AUTOSAR XML (schema 00048)
package /SecurityArchitecture/ComponentTypes
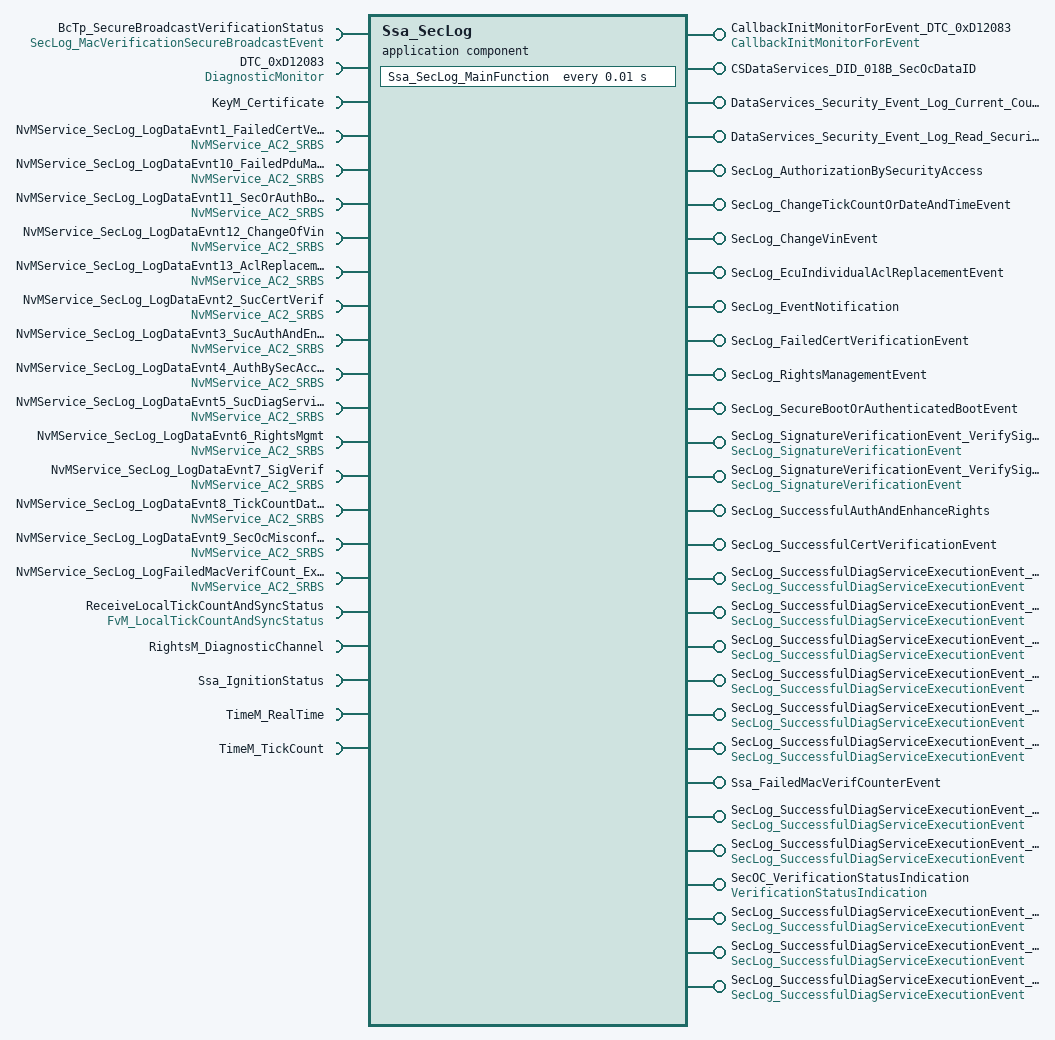
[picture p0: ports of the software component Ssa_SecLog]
  application sw component type Ssa_SecLog
    23 x provide port:
      CallbackInitMonitorForEvent_DTC_0xD12083: server-com-spec{operation=InitMonitorForEvent, queue-length=1}, provided-interface=CallbackInitMonitorForEvent  # Notifies that this event is cleared, or that the operation (monitoring) cycle restarts. Connect to corresponding event of Dem.
      CSDataServices_DID_018B_SecOcDataID: server-com-spec{operation=ReadData, queue-length=1}, provided-interface=CSDataServices_DID_018B_SecOcDataID  # Reads the SecOcDataID as Environmental Data for DTC 0xD12083. Connect to corresponding Dem port.
      DataServices_Security_Event_Log_Current_Counter_Values_Read_Security_Event_Log_Current_Counter_Values: provided-interface=DataServices_Security_Event_Log_Current_Counter_Values_Read_Security_Event_Log_Current_Counter_Values  # Reads the current counter values of the security event log.
        provided-com-specs:
          operation=ConditionCheckRead, queue-length=1
          operation=ReadData, queue-length=1
          operation=ReadDataLength, queue-length=1
      DataServices_Security_Event_Log_Read_Security_Event_Log_Entry: provided-interface=DataServices_Security_Event_Log_Read_Security_Event_Log_Entry  # Reads security event log.
        provided-com-specs:
          operation=ConditionCheckRead, queue-length=1
          operation=ReadData, queue-length=1
          operation=ReadDataLength, queue-length=1
      SecLog_AuthorizationBySecurityAccess: server-com-spec{operation=AuthorizationBySecurityAccess, queue-length=1}, provided-interface=SecLog_AuthorizationBySecurityAccess
      SecLog_ChangeTickCountOrDateAndTimeEvent: server-com-spec{operation=ChangeTickCountOrDateAndTime, queue-length=1}, provided-interface=SecLog_ChangeTickCountOrDateAndTimeEvent
      SecLog_ChangeVinEvent: server-com-spec{operation=ChangeVin, queue-length=1}, provided-interface=SecLog_ChangeVinEvent
      SecLog_EcuIndividualAclReplacementEvent: server-com-spec{operation=EcuIndividualAclReplacement, queue-length=1}, provided-interface=SecLog_EcuIndividualAclReplacementEvent
      SecLog_EventNotification: nonqueued-sender-com-spec{data-element=Data, init-value=constant-reference=Ssa_Init_Zero_7Byte}, provided-interface=SecLog_EventNotification
      SecLog_FailedCertVerificationEvent: server-com-spec{operation=FailedCertificateVerification, queue-length=1}, provided-interface=SecLog_FailedCertVerificationEvent
      SecLog_RightsManagementEvent: server-com-spec{operation=RightsManagement, queue-length=1}, provided-interface=SecLog_RightsManagementEvent
      SecLog_SecureBootOrAuthenticatedBootEvent: server-com-spec{operation=SecureBootOrAuthenticatedBoot, queue-length=1}, provided-interface=SecLog_SecureBootOrAuthenticatedBootEvent
      SecLog_SignatureVerificationEvent_VerifySignatureSwReprogramming: server-com-spec{operation=SignatureVerification, queue-length=1}, provided-interface=SecLog_SignatureVerificationEvent
      SecLog_SignatureVerificationEvent_VerifySignatureVariantCoding: server-com-spec{operation=SignatureVerification, queue-length=1}, provided-interface=SecLog_SignatureVerificationEvent
      SecLog_SuccessfulAuthAndEnhanceRights: server-com-spec{operation=SuccessfulAuthAndEnhanceRights, queue-length=1}, provided-interface=SecLog_SuccessfulAuthAndEnhanceRights
      SecLog_SuccessfulCertVerificationEvent: server-com-spec{operation=SuccessfulCertificateVerification, queue-length=1}, provided-interface=SecLog_SuccessfulCertVerificationEvent
      SecLog_SuccessfulDiagServiceExecutionEvent_ActivateDebugIf: server-com-spec{operation=SuccessfulDiagServiceExecution, queue-length=1}, provided-interface=SecLog_SuccessfulDiagServiceExecutionEvent
      SecLog_SuccessfulDiagServiceExecutionEvent_ClearSarMemory: server-com-spec{operation=SuccessfulDiagServiceExecution, queue-length=1}, provided-interface=SecLog_SuccessfulDiagServiceExecutionEvent
      SecLog_SuccessfulDiagServiceExecutionEvent_EcuSharedSecretDistribution: server-com-spec{operation=SuccessfulDiagServiceExecution, queue-length=1}, provided-interface=SecLog_SuccessfulDiagServiceExecutionEvent  # Configuration Variant(s): Not in VSM.
      SecLog_SuccessfulDiagServiceExecutionEvent_EnableSarMemOverwrite: server-com-spec{operation=SuccessfulDiagServiceExecution, queue-length=1}, provided-interface=SecLog_SuccessfulDiagServiceExecutionEvent
      SecLog_SuccessfulDiagServiceExecutionEvent_EraseMemory: server-com-spec{operation=SuccessfulDiagServiceExecution, queue-length=1}, provided-interface=SecLog_SuccessfulDiagServiceExecutionEvent
      SecLog_SuccessfulDiagServiceExecutionEvent_ReplaceCert: server-com-spec{operation=SuccessfulDiagServiceExecution, queue-length=1}, provided-interface=SecLog_SuccessfulDiagServiceExecutionEvent
      Ssa_FailedMacVerifCounterEvent: queued-sender-com-spec=Event, provided-interface=Ssa_FailedMacVerifCounterEvent
    24 x require port:
      BcTp_SecureBroadcastVerificationStatus: nonqueued-receiver-com-spec{data-element=verificationStatus, filter=data-filter-type=ALWAYS, init-value=constant-reference=Ssa_Init_SecOcVerificationState}, required-interface=SecLog_MacVerificationSecureBroadcastEvent  # Configuration Variant(s): Not in VSM.
      DTC_0xD12083: required-com-specs=[ResetEventDebounceStatus, ResetEventStatus, SetEventStatus], required-interface=DiagnosticMonitor  # Set an Event Status to failed if any one of the PDU-specific counters exceeds its configured threshold. Connect to corresponding event of Dem.
      KeyM_Certificate: required-interface=KeyM_Certificate
        required-com-specs:
          GetBackendSerialNumber
          GetBackendSubject
          VerifyCertWithBackendCert
          SignData4092ByteWithEcuPrivateKey
          VerifyCertWithBackendCert
          SignData1024ByteWithEcuPrivateKey
          CheckTrustModelChainOfTrust
      NvMService_SecLog_LogDataEvnt1_FailedCertVerif: required-com-specs=[GetErrorStatus, ReadBlock, SetRamBlockStatus, WriteBlock], required-interface=NvMService_AC2_SRBS  # Controlling the NvM block which stores the security log data of event 1, "Failed certificate verification". Connect to NvM block storing the the security log data of event 1.
      NvMService_SecLog_LogDataEvnt10_FailedPduMacVerif: required-com-specs=[GetErrorStatus, ReadBlock, SetRamBlockStatus, WriteBlock], required-interface=NvMService_AC2_SRBS  # Controlling the NvM block which stores the security log data of event 10, "Failed PDU MAC verification". Connect to NvM block storing the the security log data of event 10.
      NvMService_SecLog_LogDataEvnt11_SecOrAuthBoot: required-com-specs=[GetErrorStatus, ReadBlock, SetRamBlockStatus, WriteBlock], required-interface=NvMService_AC2_SRBS  # Controlling the NvM block which stores the security log data of event 11, "Secure boot or authenticated boot". Connect to NvM block storing the the security log data of event 11.
      NvMService_SecLog_LogDataEvnt12_ChangeOfVin: required-com-specs=[GetErrorStatus, ReadBlock, SetRamBlockStatus, WriteBlock], required-interface=NvMService_AC2_SRBS  # Controlling the NvM block which stores the security log data of event 12, "Change of VIN". Connect to NvM block storing the the security log data of event 12.
      NvMService_SecLog_LogDataEvnt13_AclReplacement: required-com-specs=[GetErrorStatus, ReadBlock, SetRamBlockStatus, WriteBlock], required-interface=NvMService_AC2_SRBS  # Controlling the NvM block which stores the security log data of event 13, "ECU-individual AccessControlList replacement". Connect to NvM block storing the the security log data of event 13.
      NvMService_SecLog_LogDataEvnt2_SucCertVerif: required-com-specs=[GetErrorStatus, ReadBlock, SetRamBlockStatus, WriteBlock], required-interface=NvMService_AC2_SRBS  # Controlling the NvM block which stores the security log data of event 2, "Successful certificate verification". Connect to NvM block storing the the security log data of event 2.
      NvMService_SecLog_LogDataEvnt3_SucAuthAndEnhanceRights: required-com-specs=[GetErrorStatus, ReadBlock, SetRamBlockStatus, WriteBlock], required-interface=NvMService_AC2_SRBS  # Controlling the NvM block which stores the security log data of event 3, "Successful authentication and enhance rights". Connect to NvM block storing the the security log data of event 3.
      NvMService_SecLog_LogDataEvnt4_AuthBySecAccess: required-com-specs=[GetErrorStatus, ReadBlock, SetRamBlockStatus, WriteBlock], required-interface=NvMService_AC2_SRBS  # Controlling the NvM block which stores the security log data of event 4, "Authorization by Security Access". Connect to NvM block storing the the security log data of event 4.
      NvMService_SecLog_LogDataEvnt5_SucDiagServiceExec: required-com-specs=[GetErrorStatus, ReadBlock, SetRamBlockStatus, WriteBlock], required-interface=NvMService_AC2_SRBS  # Controlling the NvM block which stores the security log data of event 5, "Successful diagnostic service execution". Connect to NvM block storing the the security log data of event 5.
      NvMService_SecLog_LogDataEvnt6_RightsMgmt: required-com-specs=[GetErrorStatus, ReadBlock, SetRamBlockStatus, WriteBlock], required-interface=NvMService_AC2_SRBS  # Controlling the NvM block which stores the security log data of event 6, "Rights management". Connect to NvM block storing the the security log data of event 6.
      NvMService_SecLog_LogDataEvnt7_SigVerif: required-com-specs=[GetErrorStatus, ReadBlock, SetRamBlockStatus, WriteBlock], required-interface=NvMService_AC2_SRBS  # Controlling the NvM block which stores the security log data of event 7, "Signature verification". Connect to NvM block storing the the security log data of event 7.
      NvMService_SecLog_LogDataEvnt8_TickCountDateAndTime: required-com-specs=[GetErrorStatus, ReadBlock, SetRamBlockStatus, WriteBlock], required-interface=NvMService_AC2_SRBS  # Controlling the NvM block which stores the security log data of event 8, "Change of tick count or date and time". Connect to NvM block storing the the security log data of event 8.
      NvMService_SecLog_LogDataEvnt9_SecOcMisconfig: required-com-specs=[GetErrorStatus, ReadBlock, SetRamBlockStatus, WriteBlock], required-interface=NvMService_AC2_SRBS  # Controlling the NvM block which stores the security log data of event 9, "SecOC misconfiguration". Connect to NvM block storing the the security log data of event 9.
      NvMService_SecLog_LogFailedMacVerifCount_ExceededTh{1..3}: required-com-specs=[GetErrorStatus, ReadBlock, SetRamBlockStatus, WriteBlock], required-interface=NvMService_AC2_SRBS  # Controlling the NvM block which stores the security log data of counter Exceeded Threshold {1..3} (belonging to event 10, Failed PDU MAC verification). Connect to NvM block storing this data.
      ReceiveLocalTickCountAndSyncStatus: nonqueued-receiver-com-spec{data-element=Data, filter=data-filter-type=ALWAYS, init-value=constant-reference=Ssa_Init_LocalTickCountAndSyncStatus}, required-interface=FvM_LocalTickCountAndSyncStatus
      RightsM_DiagnosticChannel: required-com-specs=[GetDiagChanAndAuthStatus, GetDiagnosticUserRole, GetDiagnosticUserRolesBitMask, GetPostProductionStatus], required-interface=RightsM_DiagnosticChannel
      Ssa_IgnitionStatus: nonqueued-receiver-com-spec{data-element=Ign_Stat_Pr5_ST3, end-to-end-transformation-com-spec-props=disable-end-to-end-check=true, filter=data-filter-type=ALWAYS, init-value=constant-reference=Ssa_Init_IgnitionStatus}, required-interface=Ssa_IgnitionStatus
      TimeM_RealTime: required-com-specs=[Compare, Get, Set], required-interface=TimeM_RealTime
      TimeM_TickCount: client-com-spec=Get, required-interface=TimeM_TickCount
    6 x provide port:
      SecLog_SuccessfulDiagServiceExecutionEvent_ReplaceTrustModelCert: server-com-spec{operation=SuccessfulDiagServiceExecution, queue-length=1}, provided-interface=SecLog_SuccessfulDiagServiceExecutionEvent
      SecLog_SuccessfulDiagServiceExecutionEvent_ReplaceTrustModeRootCert: server-com-spec{operation=SuccessfulDiagServiceExecution, queue-length=1}, provided-interface=SecLog_SuccessfulDiagServiceExecutionEvent
      SecOC_VerificationStatusIndication: server-com-spec{operation=VerifyStatus, queue-length=1}, provided-interface=VerificationStatusIndication  # Notifies via client-server port about a failed SecOC Mac verification, collects the data and creates a security log event. Connect to SecOC indication port.
      SecLog_SuccessfulDiagServiceExecutionEvent_InjectSeed: server-com-spec{operation=SuccessfulDiagServiceExecution, queue-length=1}, provided-interface=SecLog_SuccessfulDiagServiceExecutionEvent  # Configuration Variant(s): Not in VSM.
      SecLog_SuccessfulDiagServiceExecutionEvent_TrustModeEcuSharedSecretDistribution: server-com-spec{operation=SuccessfulDiagServiceExecution, queue-length=1}, provided-interface=SecLog_SuccessfulDiagServiceExecutionEvent  # Configuration Variant(s): Not in VSM.
      SecLog_SuccessfulDiagServiceExecutionEvent_TrustModelGenerateKeyPair: server-com-spec{operation=SuccessfulDiagServiceExecution, queue-length=1}, provided-interface=SecLog_SuccessfulDiagServiceExecutionEvent
    behavior Ssa_SecLog_InternalBehavior: data-type-mapping=SSATypeMappingSet
      exclusive area SecLog_ExclusiveArea
      ar-typed-per-instance-memorys:
        32 x data:
          LogDataEvnt1_FailedCertVerif: type=SecLog_LogDataEvnt1_FailedCertVerifType
          LogDataEvnt1_FailedCertVerif_Mirror: type=SecLog_LogDataEvnt1_FailedCertVerifType
          LogDataEvnt10_FailedPduMacVerif: type=SecLog_LogDataEvnt10_FailedPduMacVerifType
          LogDataEvnt10_FailedPduMacVerif_Mirror: type=SecLog_LogDataEvnt10_FailedPduMacVerifType
          LogDataEvnt11_SecOrAuthBoot: type=SecLog_LogDataEvnt11_SecOrAuthBootType
          LogDataEvnt11_SecOrAuthBoot_Mirror: type=SecLog_LogDataEvnt11_SecOrAuthBootType
          LogDataEvnt12_ChangeOfVin: type=SecLog_LogDataEvnt12_ChangeOfVinType
          LogDataEvnt12_ChangeOfVin_Mirror: type=SecLog_LogDataEvnt12_ChangeOfVinType
          LogDataEvnt13_AclReplacement: type=SecLog_LogDataEvnt13_AclReplacementType
          LogDataEvnt13_AclReplacement_Mirror: type=SecLog_LogDataEvnt13_AclReplacementType
          LogDataEvnt2_SucCertVerif: type=SecLog_LogDataEvnt2_SucCertVerifType
          LogDataEvnt2_SucCertVerif_Mirror: type=SecLog_LogDataEvnt2_SucCertVerifType
          LogDataEvnt3_SucAuthAndEnhanceRights: type=SecLog_LogDataEvnt3_SucAuthAndEnhanceRightsType
          LogDataEvnt3_SucAuthAndEnhanceRights_Mirror: type=SecLog_LogDataEvnt3_SucAuthAndEnhanceRightsType
          LogDataEvnt4_AuthBySecAccess: type=SecLog_LogDataEvnt4_AuthBySecAccessType
          LogDataEvnt4_AuthBySecAccess_Mirror: type=SecLog_LogDataEvnt4_AuthBySecAccessType
          LogDataEvnt5_SucDiagServiceExec: type=SecLog_LogDataEvnt5_SucDiagServiceExecType
          LogDataEvnt5_SucDiagServiceExec_Mirror: type=SecLog_LogDataEvnt5_SucDiagServiceExecType
          LogDataEvnt6_RightsMgmt: type=SecLog_LogDataEvnt6_RightsMgmtType
          LogDataEvnt6_RightsMgmt_Mirror: type=SecLog_LogDataEvnt6_RightsMgmtType
          LogDataEvnt7_SigVerif: type=SecLog_LogDataEvnt7_SigVerifType
          LogDataEvnt7_SigVerif_Mirror: type=SecLog_LogDataEvnt7_SigVerifType
          LogDataEvnt8_TickCountDateAndTime: type=SecLog_LogDataEvnt8_TickCountDateAndTimeType
          LogDataEvnt8_TickCountDateAndTime_Mirror: type=SecLog_LogDataEvnt8_TickCountDateAndTimeType
          LogDataEvnt9_SecOcMisconfig: type=SecLog_LogDataEvnt9_SecOcMisconfigType
          LogDataEvnt9_SecOcMisconfig_Mirror: type=SecLog_LogDataEvnt9_SecOcMisconfigType
          LogFailedMacVerifCount_ExceededTh1: type=SecLog_LogFailedMacVerifCount_ExceededThType
          LogFailedMacVerifCount_ExceededTh1_Mirror: type=SecLog_LogFailedMacVerifCount_ExceededThType
          LogFailedMacVerifCount_ExceededTh2: type=SecLog_LogFailedMacVerifCount_ExceededThType
          LogFailedMacVerifCount_ExceededTh2_Mirror: type=SecLog_LogFailedMacVerifCount_ExceededThType
          LogFailedMacVerifCount_ExceededTh3: type=SecLog_LogFailedMacVerifCount_ExceededThType
          LogFailedMacVerifCount_ExceededTh3_Mirror: type=SecLog_LogFailedMacVerifCount_ExceededThType
      7 x operation invoked event:
        OIT_CSDataServices_DID_018B_SecOcDataID_ReadData_CSDataServices_DID_018B_SecOcDataID_ReadData: start-on-event=Ssa_SecLog_CSDataServices_DID_018B_SecOcDataID_ReadData, operation=CSDataServices_DID_018B_SecOcDataID.ReadData
        OIT_Ssa_SecLog_DataServices_Security_Event_Log_Current_Counter_Values_ConditionCheckRead_DataServices_Security_Event_Log0076A3D4: start-on-event=Ssa_SecLog_DataServices_Security_Event_Log_Current_Counter_Values_ConditionCheckRead, operation=DataServices_Security_Event_Log_Current_Counter_Values_Read_Security_Event_Log_Current_Counter_Values.ConditionCheckRead
        OIT_Ssa_SecLog_DataServices_Security_Event_Log_Current_Counter_Values_ReadData_DataServices_Security_Event_Log_Current_C5655AD37: start-on-event=Ssa_SecLog_DataServices_Security_Event_Log_Current_Counter_Values_ReadData, operation=DataServices_Security_Event_Log_Current_Counter_Values_Read_Security_Event_Log_Current_Counter_Values.ReadData
        OIT_Ssa_SecLog_DataServices_Security_Event_Log_Current_Counter_Values_ReadDataLength_DataServices_Security_Event_Log_CurB0E39DAE: start-on-event=Ssa_SecLog_DataServices_Security_Event_Log_Current_Counter_Values_ReadDataLength, operation=DataServices_Security_Event_Log_Current_Counter_Values_Read_Security_Event_Log_Current_Counter_Values.ReadDataLength
        OIT_Ssa_SecLog_DataServices_Security_Event_Log_Read_Security_Event_Log_Entry_ConditionCheckRead_DataServices_Security_Ev5CE827B1: start-on-event=Ssa_SecLog_DataServices_Security_Event_Log_Read_Security_Event_Log_Entry_ConditionCheckRead, operation=DataServices_Security_Event_Log_Read_Security_Event_Log_Entry.ConditionCheckRead
        OIT_Ssa_SecLog_DataServices_Security_Event_Log_Read_Security_Event_Log_Entry_ReadData_DataServices_Security_Event_Log_ReFFAA87F4: start-on-event=Ssa_SecLog_DataServices_Security_Event_Log_Read_Security_Event_Log_Entry_ReadData, operation=DataServices_Security_Event_Log_Read_Security_Event_Log_Entry.ReadData
        OIT_Ssa_SecLog_DataServices_Security_Event_Log_Read_Security_Event_Log_Entry_ReadDataLength_DataServices_Security_Event_8C8FC7BB: start-on-event=Ssa_SecLog_DataServices_Security_Event_Log_Read_Security_Event_Log_Entry_ReadDataLength, operation=DataServices_Security_Event_Log_Read_Security_Event_Log_Entry.ReadDataLength
      data received event DRT_Ssa_SecLog_IgnitionStatusChanged_Ssa_IgnitionStatus_ISw_Stat_ST3: start-on-event=Ssa_SecLog_IgnitionStatusChanged, data=Ssa_IgnitionStatus.Ign_Stat_Pr5_ST3
      init event SecLog_InitEvent: start-on-event=Ssa_SecLog_Init
      6 x operation invoked event:
        OIT_CallbackInitMonitorForEvent_DTC_0xD12083_InitMonitorForEvent_CallbackInitMonitorForEvent_DTC_0xD12083_InitMonitorForEvent: start-on-event=Ssa_SecLog_InitMonitorForEvent_DTC_0xD12083, operation=CallbackInitMonitorForEvent_DTC_0xD12083.InitMonitorForEvent
        OIT_SecLog_AuthorizationBySecurityAccess_AuthorizationBySecurityAccess_SecLog_AuthorizationBySecurityAccess_AuthorizatioB911972B: start-on-event=Ssa_SecLog_LogEvent_AuthorizationBySecurityAccess, operation=SecLog_AuthorizationBySecurityAccess.AuthorizationBySecurityAccess
        OIT_SecLog_ChangeTickCountOrDateAndTimeEvent_ChangeTickCountOrDateAndTime_SecLog_ChangeTickCountOrDateAndTimeEvent_Chang8C143075: start-on-event=Ssa_SecLog_LogEvent_ChangeTickCountOrDateAndTime, operation=SecLog_ChangeTickCountOrDateAndTimeEvent.ChangeTickCountOrDateAndTime
        OIT_SecLog_ChangeVinEvent_ChangeVin_SecLog_ChangeVinEvent_ChangeVin: start-on-event=Ssa_SecLog_LogEvent_ChangeVin, operation=SecLog_ChangeVinEvent.ChangeVin
        OIT_SecLog_EcuIndividualAclReplacementEvent_EcuIndividualAclReplacement_SecLog_EcuIndividualAclReplacementEvent_EcuIndivA0C0E014: start-on-event=Ssa_SecLog_LogEvent_EcuIndividualAclReplacement, operation=SecLog_EcuIndividualAclReplacementEvent.EcuIndividualAclReplacement
        OIT_SecLog_FailedCertVerificationEvent_FailedCertificateVerification_SecLog_FailedCertVerificationEvent_FailedCertificatB5D134F3: start-on-event=Ssa_SecLog_LogEvent_FailedCertificateVerification, operation=SecLog_FailedCertVerificationEvent.FailedCertificateVerification
      data received event DRT_Ssa_SecLog_LogEvent_FailedSecOcMacVerificationSecureBroadcast_BcTp_SecureBroadcastVerificationStatus_verificationStatus: start-on-event=Ssa_SecLog_LogEvent_FailedSecOcMacVerificationSecureBroadcast, data=BcTp_SecureBroadcastVerificationStatus.verificationStatus
      15 x operation invoked event:
        OIT_SecLog_RightsManagementNewEvent_RightsManagement_SecLog_RightsManagementNewEvent_RightsManagement: start-on-event=Ssa_SecLog_LogEvent_RightsManagement, operation=SecLog_RightsManagementEvent.RightsManagement
        OIT_SecLog_SecureBootOrAuthenticatedBootNewEvent_SecureBootOrAuthenticatedBoot_SecLog_SecureBootOrAuthenticatedBootNewEv246806E4: start-on-event=Ssa_SecLog_LogEvent_SecureBootOrAuthenticatedBoot, operation=SecLog_SecureBootOrAuthenticatedBootEvent.SecureBootOrAuthenticatedBoot
        OIT_Ssa_SecLog_LogEvent_SignatureVerification_SecLog_SignatureVerificationEvent_VerifySignatureSwReprogramming_SignatureD3B73A72: start-on-event=Ssa_SecLog_LogEvent_SignatureVerification, operation=SecLog_SignatureVerificationEvent_VerifySignatureSwReprogramming.SignatureVerification
        OIT_Ssa_SecLog_LogEvent_SignatureVerification_SecLog_SignatureVerificationEvent_VerifySignatureVariantCoding_SignatureVe2CC4CE71: start-on-event=Ssa_SecLog_LogEvent_SignatureVerification, operation=SecLog_SignatureVerificationEvent_VerifySignatureVariantCoding.SignatureVerification
        OIT_SecLog_SuccessfulAuthAndEnhanceRights_SuccessfulAuthAndEnhanceRights_SecLog_SuccessfulAuthAndEnhanceRights_Successfu875C7F52: start-on-event=Ssa_SecLog_LogEvent_SuccessfulAuthAndEnhanceRights, operation=SecLog_SuccessfulAuthAndEnhanceRights.SuccessfulAuthAndEnhanceRights
        OIT_SecLog_SuccessfulCertVerificationEvent_SuccessfulCertificateVerification_SecLog_SuccessfulCertVerificationEvent_Succ9B80BA7B: start-on-event=Ssa_SecLog_LogEvent_SuccessfulCertificateVerification, operation=SecLog_SuccessfulCertVerificationEvent.SuccessfulCertificateVerification
        OIT_SecLog_LogEvent_SuccessfulDiagServiceExecution_SecLog_SuccessfulDiagServiceExecutionEvent_ActivateDebugIf_Successful4A646E17: start-on-event=Ssa_SecLog_LogEvent_SuccessfulDiagServiceExecution, operation=SecLog_SuccessfulDiagServiceExecutionEvent_ActivateDebugIf.SuccessfulDiagServiceExecution
        OIT_SecLog_LogEvent_SuccessfulDiagServiceExecution_SecLog_SuccessfulDiagServiceExecutionEvent_ClearSarMemory_SuccessfulD898F28C9: start-on-event=Ssa_SecLog_LogEvent_SuccessfulDiagServiceExecution, operation=SecLog_SuccessfulDiagServiceExecutionEvent_ClearSarMemory.SuccessfulDiagServiceExecution
        OIT_SecLog_LogEvent_SuccessfulDiagServiceExecution_SecLog_SuccessfulDiagServiceExecutionEvent_EcuSharedSecretDistributio01731C8B: start-on-event=Ssa_SecLog_LogEvent_SuccessfulDiagServiceExecution, operation=SecLog_SuccessfulDiagServiceExecutionEvent_EcuSharedSecretDistribution.SuccessfulDiagServiceExecution
        OIT_SecLog_LogEvent_SuccessfulDiagServiceExecution_SecLog_SuccessfulDiagServiceExecutionEvent_EnableSarMemOverwrite_SuccF53BCF36: start-on-event=Ssa_SecLog_LogEvent_SuccessfulDiagServiceExecution, operation=SecLog_SuccessfulDiagServiceExecutionEvent_EnableSarMemOverwrite.SuccessfulDiagServiceExecution
        OIT_SecLog_LogEvent_SuccessfulDiagServiceExecution_SecLog_SuccessfulDiagServiceExecutionEvent_EraseMemory_SuccessfulDiag0057B662: start-on-event=Ssa_SecLog_LogEvent_SuccessfulDiagServiceExecution, operation=SecLog_SuccessfulDiagServiceExecutionEvent_EraseMemory.SuccessfulDiagServiceExecution
        OIT_SecLog_LogEvent_SuccessfulDiagServiceExecution_SecLog_SuccessfulDiagServiceExecutionEvent_ReplaceCert_SuccessfulDiag95C213A4: start-on-event=Ssa_SecLog_LogEvent_SuccessfulDiagServiceExecution, operation=SecLog_SuccessfulDiagServiceExecutionEvent_ReplaceCert.SuccessfulDiagServiceExecution
        OIT_Ssa_SecLog_LogEvent_SuccessfulDiagServiceExecution_SecLog_SuccessfulDiagServiceExecutionEvent_ReplaceTrustModelCert_26FD6FF6: start-on-event=Ssa_SecLog_LogEvent_SuccessfulDiagServiceExecution, operation=SecLog_SuccessfulDiagServiceExecutionEvent_ReplaceTrustModelCert.SuccessfulDiagServiceExecution
        OIT_Ssa_SecLog_LogEvent_SuccessfulDiagServiceExecution_SecLog_SuccessfulDiagServiceExecutionEvent_ReplaceTrustModeRootCeDF7E003D: start-on-event=Ssa_SecLog_LogEvent_SuccessfulDiagServiceExecution, operation=SecLog_SuccessfulDiagServiceExecutionEvent_ReplaceTrustModeRootCert.SuccessfulDiagServiceExecution
        OIT_Ssa_SecLog_LogEvent_SuccessfulDiagServiceExecution_SecLog_SuccessfulDiagServiceExecutionEvent_TrudtModeEcuSharedSecrF3CD2184: start-on-event=Ssa_SecLog_LogEvent_SuccessfulDiagServiceExecution, operation=SecLog_SuccessfulDiagServiceExecutionEvent_TrustModeEcuSharedSecretDistribution.SuccessfulDiagServiceExecution
      timing event TMT_SecLog_MainFunction: start-on-event=Ssa_SecLog_MainFunction, period=0.01
      operation invoked event OIT_SecOC_VerificationStatusIndication_VerifyStatus_SecOC_VerificationStatusIndication_VerifyStatus: start-on-event=Ssa_SecLog_LogEvent_FailedSecOcMacVerification, operation=SecOC_VerificationStatusIndication.VerifyStatus
      operation invoked event OIT_Ssa_SecLog_LogEvent_SuccessfulDiagServiceExecution_SecLog_SuccessfulDiagServiceExecutionEvent_InjectSeed_SuccessfulD5E0F589D: start-on-event=Ssa_SecLog_LogEvent_SuccessfulDiagServiceExecution, operation=SecLog_SuccessfulDiagServiceExecutionEvent_InjectSeed.SuccessfulDiagServiceExecution
      operation invoked event OIT_Ssa_SecLog_LogEvent_SuccessfulDiagServiceExecution_SecLog_SuccessfulDiagServiceExecutionEvent_TrustModelGenerateKeyPAD804FDF: start-on-event=Ssa_SecLog_LogEvent_SuccessfulDiagServiceExecution, operation=SecLog_SuccessfulDiagServiceExecutionEvent_TrustModelGenerateKeyPair.SuccessfulDiagServiceExecution
      port-api-options:
        enable-take-address=false, error-handling=NO-TRANSFORMER-ERROR-HANDLING, indirect-api=false, port=DTC_0xD12083
        enable-take-address=false, error-handling=NO-TRANSFORMER-ERROR-HANDLING, indirect-api=false, port=KeyM_Certificate
        enable-take-address=true, error-handling=NO-TRANSFORMER-ERROR-HANDLING, indirect-api=false, port=NvMService_SecLog_LogDataEvnt1_FailedCertVerif
        enable-take-address=true, error-handling=NO-TRANSFORMER-ERROR-HANDLING, indirect-api=false, port=NvMService_SecLog_LogDataEvnt10_FailedPduMacVerif
        enable-take-address=true, error-handling=NO-TRANSFORMER-ERROR-HANDLING, indirect-api=false, port=NvMService_SecLog_LogDataEvnt11_SecOrAuthBoot
        enable-take-address=true, error-handling=NO-TRANSFORMER-ERROR-HANDLING, indirect-api=false, port=NvMService_SecLog_LogDataEvnt12_ChangeOfVin
        enable-take-address=true, error-handling=NO-TRANSFORMER-ERROR-HANDLING, indirect-api=false, port=NvMService_SecLog_LogDataEvnt13_AclReplacement
        enable-take-address=true, error-handling=NO-TRANSFORMER-ERROR-HANDLING, indirect-api=false, port=NvMService_SecLog_LogDataEvnt2_SucCertVerif
        enable-take-address=true, error-handling=NO-TRANSFORMER-ERROR-HANDLING, indirect-api=false, port=NvMService_SecLog_LogDataEvnt3_SucAuthAndEnhanceRights
        enable-take-address=true, error-handling=NO-TRANSFORMER-ERROR-HANDLING, indirect-api=false, port=NvMService_SecLog_LogDataEvnt4_AuthBySecAccess
        enable-take-address=true, error-handling=NO-TRANSFORMER-ERROR-HANDLING, indirect-api=false, port=NvMService_SecLog_LogDataEvnt5_SucDiagServiceExec
        enable-take-address=true, error-handling=NO-TRANSFORMER-ERROR-HANDLING, indirect-api=false, port=NvMService_SecLog_LogDataEvnt6_RightsMgmt
        enable-take-address=true, error-handling=NO-TRANSFORMER-ERROR-HANDLING, indirect-api=false, port=NvMService_SecLog_LogDataEvnt7_SigVerif
        enable-take-address=true, error-handling=NO-TRANSFORMER-ERROR-HANDLING, indirect-api=false, port=NvMService_SecLog_LogDataEvnt8_TickCountDateAndTime
        enable-take-address=true, error-handling=NO-TRANSFORMER-ERROR-HANDLING, indirect-api=false, port=NvMService_SecLog_LogDataEvnt9_SecOcMisconfig
        enable-take-address=true, error-handling=NO-TRANSFORMER-ERROR-HANDLING, indirect-api=false, port=NvMService_SecLog_LogFailedMacVerifCount_ExceededTh{1..3}
        enable-take-address=false, error-handling=NO-TRANSFORMER-ERROR-HANDLING, indirect-api=false, port=RightsM_DiagnosticChannel
        enable-take-address=false, error-handling=NO-TRANSFORMER-ERROR-HANDLING, indirect-api=false, port=SecLog_AuthorizationBySecurityAccess
        enable-take-address=false, error-handling=NO-TRANSFORMER-ERROR-HANDLING, indirect-api=false, port=SecLog_ChangeTickCountOrDateAndTimeEvent
        enable-take-address=false, error-handling=NO-TRANSFORMER-ERROR-HANDLING, indirect-api=false, port=SecLog_ChangeVinEvent
        enable-take-address=false, error-handling=NO-TRANSFORMER-ERROR-HANDLING, indirect-api=false, port=SecLog_EcuIndividualAclReplacementEvent
        enable-take-address=false, error-handling=NO-TRANSFORMER-ERROR-HANDLING, indirect-api=false, port=SecLog_EventNotification
        enable-take-address=false, error-handling=NO-TRANSFORMER-ERROR-HANDLING, indirect-api=false, port=SecLog_FailedCertVerificationEvent
        enable-take-address=false, error-handling=NO-TRANSFORMER-ERROR-HANDLING, indirect-api=false, port=SecLog_RightsManagementEvent
        enable-take-address=false, error-handling=NO-TRANSFORMER-ERROR-HANDLING, indirect-api=false, port=SecLog_SecureBootOrAuthenticatedBootEvent
        {enable-take-address=false, error-handling=NO-TRANSFORMER-ERROR-HANDLING, indirect-api=false, port-defined-argument-value{value=SecLog_SignatureVerificationEvent_VerifySignatureSeReprogramming_0:0, value-type=uint8}, port=SecLog_SignatureVerificationEvent_VerifySignatureSwReprogramming}
        {enable-take-address=false, error-handling=NO-TRANSFORMER-ERROR-HANDLING, indirect-api=false, port-defined-argument-value{value=SecLog_SignatureVerificationNewEvent_VerifySignature_VariantCoding_0:1, value-type=uint8}, port=SecLog_SignatureVerificationEvent_VerifySignatureVariantCoding}
        enable-take-address=false, error-handling=NO-TRANSFORMER-ERROR-HANDLING, indirect-api=false, port=SecLog_SuccessfulAuthAndEnhanceRights
        enable-take-address=false, error-handling=NO-TRANSFORMER-ERROR-HANDLING, indirect-api=false, port=SecLog_SuccessfulCertVerificationEvent
        {enable-take-address=false, error-handling=NO-TRANSFORMER-ERROR-HANDLING, indirect-api=false, port-defined-argument-value{value=SecLog_SuccessfulDiagServiceExecutionEvent_ActivateDebugIf_0:1, value-type=uint8}, port=SecLog_SuccessfulDiagServiceExecutionEvent_ActivateDebugIf}
        {enable-take-address=false, error-handling=NO-TRANSFORMER-ERROR-HANDLING, indirect-api=false, port-defined-argument-value{value=SecLog_SuccessfulDiagServiceExecutionEvent_ClearSarMemory_0:3, value-type=uint8}, port=SecLog_SuccessfulDiagServiceExecutionEvent_ClearSarMemory}
        {enable-take-address=false, error-handling=NO-TRANSFORMER-ERROR-HANDLING, indirect-api=false, port-defined-argument-value{value=SecLog_SuccessfulDiagServiceExecutionEvent_EcuSharedSecretDistribution_0:7, value-type=uint8}, port=SecLog_SuccessfulDiagServiceExecutionEvent_EcuSharedSecretDistribution}
        {enable-take-address=false, error-handling=NO-TRANSFORMER-ERROR-HANDLING, indirect-api=false, port-defined-argument-value{value=SecLog_SuccessfulDiagServiceExecutionEvent_EnableSarMemOverwrite_0:4, value-type=uint8}, port=SecLog_SuccessfulDiagServiceExecutionEvent_EnableSarMemOverwrite}
        {enable-take-address=false, error-handling=NO-TRANSFORMER-ERROR-HANDLING, indirect-api=false, port-defined-argument-value{value=SecLog_SuccessfulDiagServiceExecutionEvent_EraseMemory_0:2, value-type=uint8}, port=SecLog_SuccessfulDiagServiceExecutionEvent_EraseMemory}
        {enable-take-address=false, error-handling=NO-TRANSFORMER-ERROR-HANDLING, indirect-api=false, port-defined-argument-value{value=SecLog_SuccessfulDiagServiceExecutionEvent_ReplaceCert_0:0, value-type=uint8}, port=SecLog_SuccessfulDiagServiceExecutionEvent_ReplaceCert}
        enable-take-address=false, error-handling=NO-TRANSFORMER-ERROR-HANDLING, indirect-api=false, port=Ssa_IgnitionStatus
        enable-take-address=false, error-handling=NO-TRANSFORMER-ERROR-HANDLING, indirect-api=false, port=TimeM_RealTime
        enable-take-address=false, error-handling=NO-TRANSFORMER-ERROR-HANDLING, indirect-api=false, port=TimeM_TickCount
        {enable-take-address=false, error-handling=NO-TRANSFORMER-ERROR-HANDLING, indirect-api=false, port-defined-argument-value{value=SecLog_SuccessfulDiagServiceExecutionEvent_ReplaceTrustModelCert_0:10, value-type=uint8}, port=SecLog_SuccessfulDiagServiceExecutionEvent_ReplaceTrustModelCert}
        {enable-take-address=false, error-handling=NO-TRANSFORMER-ERROR-HANDLING, indirect-api=false, port-defined-argument-value{value=SecLog_SuccessfulDiagServiceExecutionEvent_ReplaceTrustModeRootCert_0:11, value-type=uint8}, port=SecLog_SuccessfulDiagServiceExecutionEvent_ReplaceTrustModeRootCert}
        {enable-take-address=false, error-handling=NO-TRANSFORMER-ERROR-HANDLING, indirect-api=false, port-defined-argument-value{value=SecLog_SuccessfulDiagServiceExecutionEvent_InjectSeed_0:17, value-type=uint8}, port=SecLog_SuccessfulDiagServiceExecutionEvent_InjectSeed}
        {enable-take-address=false, error-handling=NO-TRANSFORMER-ERROR-HANDLING, indirect-api=false, port-defined-argument-value{value=SecLog_SuccessfulDiagServiceExecutionEvent_TrudtModeEcuSharedSecretDistribution_0:13, value-type=uint8}, port=SecLog_SuccessfulDiagServiceExecutionEvent_TrustModeEcuSharedSecretDistribution}
        {enable-take-address=false, error-handling=NO-TRANSFORMER-ERROR-HANDLING, indirect-api=false, port-defined-argument-value{value=SecLog_SuccessfulDiagServiceExecutionEvent_TrustModelGenerateKeyPair_0:16, value-type=uint8}, port=SecLog_SuccessfulDiagServiceExecutionEvent_TrustModelGenerateKeyPair}
      24 x runnable:
        Ssa_SecLog_CSDataServices_DID_018B_SecOcDataID_ReadData: can-be-invoked-concurrently=true
        Ssa_SecLog_DataServices_Security_Event_Log_Current_Counter_Values_ConditionCheckRead: can-enter-exclusive-area=SecLog_ExclusiveArea
        Ssa_SecLog_DataServices_Security_Event_Log_Current_Counter_Values_ReadData: can-enter-exclusive-area=SecLog_ExclusiveArea
          sync call SC_KeyM_Certificate_SignData1024ByteWithEcuPrivateKey: operation=KeyM_Certificate.SignData1024ByteWithEcuPrivateKey
        Ssa_SecLog_DataServices_Security_Event_Log_Current_Counter_Values_ReadDataLength: can-enter-exclusive-area=SecLog_ExclusiveArea
        Ssa_SecLog_DataServices_Security_Event_Log_Read_Security_Event_Log_Entry_ConditionCheckRead: can-enter-exclusive-area=SecLog_ExclusiveArea
        Ssa_SecLog_DataServices_Security_Event_Log_Read_Security_Event_Log_Entry_ReadData: can-enter-exclusive-area=SecLog_ExclusiveArea
          sync call SC_KeyM_Certificate_SignDataWithEcuPrivateKey: operation=KeyM_Certificate.SignData4092ByteWithEcuPrivateKey
          sync call SC_TimeM_Control_TimeM_GetLocalTimeBase: operation=TimeM_TickCount.Get
          sync call SC_TimeM_RealTime_TimeM_GetRealTime: operation=TimeM_RealTime.Get
        Ssa_SecLog_DataServices_Security_Event_Log_Read_Security_Event_Log_Entry_ReadDataLength: can-enter-exclusive-area=SecLog_ExclusiveArea
        Ssa_SecLog_IgnitionStatusChanged
          data-receive-point-by-arguments:
            access REC_Ssa_IgnitionStatus_ISw_Stat_ST3: accessed-variable=Ssa_IgnitionStatus.Ign_Stat_Pr5_ST3
        Ssa_SecLog_Init
          16 x sync call:
            SC_NvMService_SecLog_LogDataEvnt1_FailedCertVerif_GetErrorStatus: operation=NvMService_SecLog_LogDataEvnt1_FailedCertVerif.GetErrorStatus
            SC_NvMService_SecLog_LogDataEvnt10_FailedPduMacVerif_GetErrorStatus: operation=NvMService_SecLog_LogDataEvnt10_FailedPduMacVerif.GetErrorStatus
            SC_NvMService_SecLog_LogDataEvnt11_SecOrAuthBoot_GetErrorStatus: operation=NvMService_SecLog_LogDataEvnt11_SecOrAuthBoot.GetErrorStatus
            SC_NvMService_SecLog_LogDataEvnt12_ChangeOfVin_GetErrorStatus: operation=NvMService_SecLog_LogDataEvnt12_ChangeOfVin.GetErrorStatus
            SC_NvMService_SecLog_LogDataEvnt13_AclReplacement_GetErrorStatus: operation=NvMService_SecLog_LogDataEvnt13_AclReplacement.GetErrorStatus
            SC_NvMService_SecLog_LogDataEvnt2_SucCertVerif_GetErrorStatus: operation=NvMService_SecLog_LogDataEvnt2_SucCertVerif.GetErrorStatus
            SC_NvMService_SecLog_LogDataEvnt3_SucAuthAndEnhanceRights_GetErrorStatus: operation=NvMService_SecLog_LogDataEvnt3_SucAuthAndEnhanceRights.GetErrorStatus
            SC_NvMService_SecLog_LogDataEvnt4_AuthBySecAccess_GetErrorStatus: operation=NvMService_SecLog_LogDataEvnt4_AuthBySecAccess.GetErrorStatus
            SC_NvMService_SecLog_LogDataEvnt5_SucDiagServiceExec_GetErrorStatus: operation=NvMService_SecLog_LogDataEvnt5_SucDiagServiceExec.GetErrorStatus
            SC_NvMService_SecLog_LogDataEvnt6_RightsMgmt_GetErrorStatus: operation=NvMService_SecLog_LogDataEvnt6_RightsMgmt.GetErrorStatus
            SC_NvMService_SecLog_LogDataEvnt7_SigVerif_GetErrorStatus: operation=NvMService_SecLog_LogDataEvnt7_SigVerif.GetErrorStatus
            SC_NvMService_SecLog_LogDataEvnt8_TickCountDateAndTime_GetErrorStatus: operation=NvMService_SecLog_LogDataEvnt8_TickCountDateAndTime.GetErrorStatus
            SC_NvMService_SecLog_LogDataEvnt9_SecOcMisconfig_GetErrorStatus: operation=NvMService_SecLog_LogDataEvnt9_SecOcMisconfig.GetErrorStatus
            SC_NvMService_SecLog_LogFailedMacVerifCount_ExceededTh{1..3}_GetErrorStatus: operation=NvMService_SecLog_LogFailedMacVerifCount_ExceededTh{1..3}.GetErrorStatus
        Ssa_SecLog_InitMonitorForEvent_DTC_0xD12083
        Ssa_SecLog_LogEvent_AuthorizationBySecurityAccess: can-enter-exclusive-area=SecLog_ExclusiveArea, can-be-invoked-concurrently=true
          data-send-points:
            access SEND_SecLog_EventNotification_event: accessed-variable=SecLog_EventNotification.Data
          sync call SC_RightsM_DiagnosticChannel_GetDiagChanAndAuthStatus: operation=RightsM_DiagnosticChannel.GetDiagChanAndAuthStatus
          sync call SC_TimeM_TickCount_Get: operation=TimeM_TickCount.Get
        Ssa_SecLog_LogEvent_ChangeTickCountOrDateAndTime: can-enter-exclusive-area=SecLog_ExclusiveArea, can-be-invoked-concurrently=true
          data-send-points:
            access SEND_SecLog_EventNotification_event: accessed-variable=SecLog_EventNotification.Data
          sync call SC_TimeM_TickCount_Get: operation=TimeM_TickCount.Get
        Ssa_SecLog_LogEvent_ChangeVin: can-enter-exclusive-area=SecLog_ExclusiveArea, can-be-invoked-concurrently=true
          data-send-points:
            access SEND_SecLog_EventNotification_event: accessed-variable=SecLog_EventNotification.Data
          sync call SC_TimeM_TickCount_Get: operation=TimeM_TickCount.Get
        Ssa_SecLog_LogEvent_EcuIndividualAclReplacement: can-enter-exclusive-area=SecLog_ExclusiveArea, can-be-invoked-concurrently=true
          data-send-points:
            access SEND_SecLog_EventNotification_event: accessed-variable=SecLog_EventNotification.Data
          sync call SC_TimeM_TickCount_Get: operation=TimeM_TickCount.Get
        Ssa_SecLog_LogEvent_FailedCertificateVerification: can-enter-exclusive-area=SecLog_ExclusiveArea, can-be-invoked-concurrently=true
          data-send-points:
            access SEND_SecLog_EventNotification_event: accessed-variable=SecLog_EventNotification.Data
          sync call SC_RightsM_DiagnosticChannel_GetDiagChanAndAuthenticationState: operation=RightsM_DiagnosticChannel.GetDiagChanAndAuthStatus
          sync call SC_TimeM_TickCount_Get: operation=TimeM_TickCount.Get
        Ssa_SecLog_LogEvent_FailedSecOcMacVerification: can-enter-exclusive-area=SecLog_ExclusiveArea, can-be-invoked-concurrently=true
          data-send-points:
            access SEND_SecLog_EventNotification_Data: accessed-variable=SecLog_EventNotification.Data
            access SEND_Ssa_FailedMacVerifCounterEvent_Event: accessed-variable=Ssa_FailedMacVerifCounterEvent.Event
          sync call SC_DTC_0xD12083_SetEventStatus: operation=DTC_0xD12083.SetEventStatus
          sync call SC_TimeM_TickCount_Get: operation=TimeM_TickCount.Get
        Ssa_SecLog_LogEvent_FailedSecOcMacVerificationSecureBroadcast: can-enter-exclusive-area=SecLog_ExclusiveArea, can-be-invoked-concurrently=true  # Configuration Variant(s): Not in VSM.
          data-receive-point-by-arguments:
            access REC_BcTp_SecureBroadcastVerificationStatus_verificationStatus: accessed-variable=BcTp_SecureBroadcastVerificationStatus.verificationStatus
          data-send-points:
            access SEND_SecLog_EventNotification_event: accessed-variable=SecLog_EventNotification.Data
            access SEND_Ssa_MacAttackEvent_Event: accessed-variable=Ssa_FailedMacVerifCounterEvent.Event
          sync call SC_DTC_0xD12083_SetEventStatus: operation=DTC_0xD12083.SetEventStatus
          sync call SC_TimeM_TickCount_Get: operation=TimeM_TickCount.Get
        Ssa_SecLog_LogEvent_RightsManagement: can-enter-exclusive-area=SecLog_ExclusiveArea, can-be-invoked-concurrently=true
          data-send-points:
            access SEND_SecLog_EventNotification_event: accessed-variable=SecLog_EventNotification.Data
          sync call SC_TimeM_TickCount_Get: operation=TimeM_TickCount.Get
        Ssa_SecLog_LogEvent_SecureBootOrAuthenticatedBoot: can-enter-exclusive-area=SecLog_ExclusiveArea, can-be-invoked-concurrently=true
          data-send-points:
            access SEND_SecLog_EventNotification_event: accessed-variable=SecLog_EventNotification.Data
          sync call SC_TimeM_TickCount_Get: operation=TimeM_TickCount.Get
        Ssa_SecLog_LogEvent_SignatureVerification: can-enter-exclusive-area=SecLog_ExclusiveArea, can-be-invoked-concurrently=true
          data-send-points:
            access SEND_SecLog_EventNotification_event: accessed-variable=SecLog_EventNotification.Data
          sync call SC_RightsM_DiagnosticChannel_GetDiagChanAndAuthStatus: operation=RightsM_DiagnosticChannel.GetDiagChanAndAuthStatus
          sync call SC_TimeM_TickCount_Get: operation=TimeM_TickCount.Get
        Ssa_SecLog_LogEvent_SuccessfulAuthAndEnhanceRights: can-enter-exclusive-area=SecLog_ExclusiveArea, can-be-invoked-concurrently=true
          data-send-points:
            access SEND_SecLog_EventNotification_event: accessed-variable=SecLog_EventNotification.Data
          sync call SC_TimeM_TickCount_Get: operation=TimeM_TickCount.Get
        Ssa_SecLog_LogEvent_SuccessfulCertificateVerification: can-enter-exclusive-area=SecLog_ExclusiveArea, can-be-invoked-concurrently=true
          data-send-points:
            access SEND_SecLog_EventNotification_event: accessed-variable=SecLog_EventNotification.Data
          sync call SC_RightsM_DiagnosticChannel_GetDiagChanAndAuthenticationState: operation=RightsM_DiagnosticChannel.GetDiagChanAndAuthStatus
          sync call SC_TimeM_TickCount_Get: operation=TimeM_TickCount.Get
        Ssa_SecLog_LogEvent_SuccessfulDiagServiceExecution: can-enter-exclusive-area=SecLog_ExclusiveArea, can-be-invoked-concurrently=true
          data-send-points:
            access SEND_SecLog_EventNotification_event: accessed-variable=SecLog_EventNotification.Data
          sync call SC_RightsM_DiagnosticChannel_GetDiagChanAndAuthenticationState: operation=RightsM_DiagnosticChannel.GetDiagChanAndAuthStatus
          sync call SC_TimeM_TickCount_Get: operation=TimeM_TickCount.Get
        Ssa_SecLog_MainFunction: can-enter-exclusive-area=SecLog_ExclusiveArea
          data-receive-point-by-arguments:
            access REC_ReceiveLocalTickCountAndSyncStatus_Data: accessed-variable=ReceiveLocalTickCountAndSyncStatus.Data
          data-send-points:
            access SEND_SecLog_EventNotification_Data: accessed-variable=SecLog_EventNotification.Data
          48 x sync call:
            SC_NvMService_SecLog_LogDataEvnt1_FailedCertVerif_GetErrorStatus: operation=NvMService_SecLog_LogDataEvnt1_FailedCertVerif.GetErrorStatus
            SC_NvMService_SecLog_LogDataEvnt1_FailedCertVerif_SetRamBlockStatus: operation=NvMService_SecLog_LogDataEvnt1_FailedCertVerif.SetRamBlockStatus
            SC_NvMService_SecLog_LogDataEvnt1_FailedCertVerif_WriteBlock: operation=NvMService_SecLog_LogDataEvnt1_FailedCertVerif.WriteBlock
            SC_NvMService_SecLog_LogDataEvnt10_FailedPduMacVerif_GetErrorStatus: operation=NvMService_SecLog_LogDataEvnt10_FailedPduMacVerif.GetErrorStatus
            SC_NvMService_SecLog_LogDataEvnt10_FailedPduMacVerif_SetRamBlockStatus: operation=NvMService_SecLog_LogDataEvnt10_FailedPduMacVerif.SetRamBlockStatus
            SC_NvMService_SecLog_LogDataEvnt10_FailedPduMacVerif_WriteBlock: operation=NvMService_SecLog_LogDataEvnt10_FailedPduMacVerif.WriteBlock
            SC_NvMService_SecLog_LogDataEvnt11_SecOrAuthBoot_GetErrorStatus: operation=NvMService_SecLog_LogDataEvnt11_SecOrAuthBoot.GetErrorStatus
            SC_NvMService_SecLog_LogDataEvnt11_SecOrAuthBoot_SetRamBlockStatus: operation=NvMService_SecLog_LogDataEvnt11_SecOrAuthBoot.SetRamBlockStatus
            SC_NvMService_SecLog_LogDataEvnt11_SecOrAuthBoot_WriteBlock: operation=NvMService_SecLog_LogDataEvnt11_SecOrAuthBoot.WriteBlock
            SC_NvMService_SecLog_LogDataEvnt12_ChangeOfVin_GetErrorStatus: operation=NvMService_SecLog_LogDataEvnt12_ChangeOfVin.GetErrorStatus
            SC_NvMService_SecLog_LogDataEvnt12_ChangeOfVin_SetRamBlockStatus: operation=NvMService_SecLog_LogDataEvnt12_ChangeOfVin.SetRamBlockStatus
            SC_NvMService_SecLog_LogDataEvnt12_ChangeOfVin_WriteBlock: operation=NvMService_SecLog_LogDataEvnt12_ChangeOfVin.WriteBlock
            SC_NvMService_SecLog_LogDataEvnt13_AclReplacement_GetErrorStatus: operation=NvMService_SecLog_LogDataEvnt13_AclReplacement.GetErrorStatus
            SC_NvMService_SecLog_LogDataEvnt13_AclReplacement_SetRamBlockStatus: operation=NvMService_SecLog_LogDataEvnt13_AclReplacement.SetRamBlockStatus
            SC_NvMService_SecLog_LogDataEvnt13_AclReplacement_WriteBlock: operation=NvMService_SecLog_LogDataEvnt13_AclReplacement.WriteBlock
            SC_NvMService_SecLog_LogDataEvnt2_SucCertVerif_GetErrorStatus: operation=NvMService_SecLog_LogDataEvnt2_SucCertVerif.GetErrorStatus
            SC_NvMService_SecLog_LogDataEvnt2_SucCertVerif_SetRamBlockStatus: operation=NvMService_SecLog_LogDataEvnt2_SucCertVerif.SetRamBlockStatus
            SC_NvMService_SecLog_LogDataEvnt2_SucCertVerif_WriteBlock: operation=NvMService_SecLog_LogDataEvnt2_SucCertVerif.WriteBlock
            SC_NvMService_SecLog_LogDataEvnt3_SucAuthAndEnhanceRights_GetErrorStatus: operation=NvMService_SecLog_LogDataEvnt3_SucAuthAndEnhanceRights.GetErrorStatus
            SC_NvMService_SecLog_LogDataEvnt3_SucAuthAndEnhanceRights_SetRamBlockStatus: operation=NvMService_SecLog_LogDataEvnt3_SucAuthAndEnhanceRights.SetRamBlockStatus
            SC_NvMService_SecLog_LogDataEvnt3_SucAuthAndEnhanceRights_WriteBlock: operation=NvMService_SecLog_LogDataEvnt3_SucAuthAndEnhanceRights.WriteBlock
            SC_NvMService_SecLog_LogDataEvnt4_AuthBySecAccess_GetErrorStatus: operation=NvMService_SecLog_LogDataEvnt4_AuthBySecAccess.GetErrorStatus
            SC_NvMService_SecLog_LogDataEvnt4_AuthBySecAccess_SetRamBlockStatus: operation=NvMService_SecLog_LogDataEvnt4_AuthBySecAccess.SetRamBlockStatus
            SC_NvMService_SecLog_LogDataEvnt4_AuthBySecAccess_WriteBlock: operation=NvMService_SecLog_LogDataEvnt4_AuthBySecAccess.WriteBlock
            SC_NvMService_SecLog_LogDataEvnt5_SucDiagServiceExec_GetErrorStatus: operation=NvMService_SecLog_LogDataEvnt5_SucDiagServiceExec.GetErrorStatus
            SC_NvMService_SecLog_LogDataEvnt5_SucDiagServiceExec_SetRamBlockStatus: operation=NvMService_SecLog_LogDataEvnt5_SucDiagServiceExec.SetRamBlockStatus
            SC_NvMService_SecLog_LogDataEvnt5_SucDiagServiceExec_WriteBlock: operation=NvMService_SecLog_LogDataEvnt5_SucDiagServiceExec.WriteBlock
            SC_NvMService_SecLog_LogDataEvnt6_RightsMgmt_GetErrorStatus: operation=NvMService_SecLog_LogDataEvnt6_RightsMgmt.GetErrorStatus
            SC_NvMService_SecLog_LogDataEvnt6_RightsMgmt_SetRamBlockStatus: operation=NvMService_SecLog_LogDataEvnt6_RightsMgmt.SetRamBlockStatus
            SC_NvMService_SecLog_LogDataEvnt6_RightsMgmt_WriteBlock: operation=NvMService_SecLog_LogDataEvnt6_RightsMgmt.WriteBlock
            SC_NvMService_SecLog_LogDataEvnt7_SigVerif_GetErrorStatus: operation=NvMService_SecLog_LogDataEvnt7_SigVerif.GetErrorStatus
            SC_NvMService_SecLog_LogDataEvnt7_SigVerif_SetRamBlockStatus: operation=NvMService_SecLog_LogDataEvnt7_SigVerif.SetRamBlockStatus
            SC_NvMService_SecLog_LogDataEvnt7_SigVerif_WriteBlock: operation=NvMService_SecLog_LogDataEvnt7_SigVerif.WriteBlock
            SC_NvMService_SecLog_LogDataEvnt8_TickCountDateAndTime_GetErrorStatus: operation=NvMService_SecLog_LogDataEvnt8_TickCountDateAndTime.GetErrorStatus
            SC_NvMService_SecLog_LogDataEvnt8_TickCountDateAndTime_SetRamBlockStatus: operation=NvMService_SecLog_LogDataEvnt8_TickCountDateAndTime.SetRamBlockStatus
            SC_NvMService_SecLog_LogDataEvnt8_TickCountDateAndTime_WriteBlock: operation=NvMService_SecLog_LogDataEvnt8_TickCountDateAndTime.WriteBlock
            SC_NvMService_SecLog_LogDataEvnt9_SecOcMisconfig_GetErrorStatus: operation=NvMService_SecLog_LogDataEvnt9_SecOcMisconfig.GetErrorStatus
            SC_NvMService_SecLog_LogDataEvnt9_SecOcMisconfig_SetRamBlockStatus: operation=NvMService_SecLog_LogDataEvnt9_SecOcMisconfig.SetRamBlockStatus
            SC_NvMService_SecLog_LogDataEvnt9_SecOcMisconfig_WriteBlock: operation=NvMService_SecLog_LogDataEvnt9_SecOcMisconfig.WriteBlock
            SC_NvMService_SecLog_LogFailedMacVerifCount_ExceededTh1_GetErrorStatus: operation=NvMService_SecLog_LogFailedMacVerifCount_ExceededTh1.GetErrorStatus
            SC_NvMService_SecLog_LogFailedMacVerifCount_ExceededTh1_SetRamBlockStatus: operation=NvMService_SecLog_LogFailedMacVerifCount_ExceededTh1.SetRamBlockStatus
            SC_NvMService_SecLog_LogFailedMacVerifCount_ExceededTh1_WriteBlock: operation=NvMService_SecLog_LogFailedMacVerifCount_ExceededTh1.WriteBlock
            SC_NvMService_SecLog_LogFailedMacVerifCount_ExceededTh2_GetErrorStatus: operation=NvMService_SecLog_LogFailedMacVerifCount_ExceededTh2.GetErrorStatus
            SC_NvMService_SecLog_LogFailedMacVerifCount_ExceededTh2_SetRamBlockStatus: operation=NvMService_SecLog_LogFailedMacVerifCount_ExceededTh2.SetRamBlockStatus
            SC_NvMService_SecLog_LogFailedMacVerifCount_ExceededTh2_WriteBlock: operation=NvMService_SecLog_LogFailedMacVerifCount_ExceededTh2.WriteBlock
            SC_NvMService_SecLog_LogFailedMacVerifCount_ExceededTh3_GetErrorStatus: operation=NvMService_SecLog_LogFailedMacVerifCount_ExceededTh3.GetErrorStatus
            SC_NvMService_SecLog_LogFailedMacVerifCount_ExceededTh3_SetRamBlockStatus: operation=NvMService_SecLog_LogFailedMacVerifCount_ExceededTh3.SetRamBlockStatus
            SC_NvMService_SecLog_LogFailedMacVerifCount_ExceededTh3_WriteBlock: operation=NvMService_SecLog_LogFailedMacVerifCount_ExceededTh3.WriteBlock
      16 x swc service dependency:
        NvM_SecLog_LogDataEvnt1_FailedCertVerif: assigned-datas=role-based-data-assignment={role=ramBlock, used-data-element=LogDataEvnt1_FailedCertVerif}
          service-needs:
            nv block needs NvM_SecLog_LogDataEvnt1_FailedCertVerif: ram-block-status-control=API, restore-at-start=true, store-at-shutdown=true
        NvM_SecLog_LogDataEvnt2_SucCertVerif: assigned-datas=role-based-data-assignment={role=ramBlock, used-data-element=LogDataEvnt2_SucCertVerif}
          service-needs:
            nv block needs NvM_SecLog_LogDataEvnt2_SucCertVerif: ram-block-status-control=API, restore-at-start=true, store-at-shutdown=true
        NvM_SecLog_LogDataEvnt3_SucAuthAndEnhanceRights: assigned-datas=role-based-data-assignment={role=ramBlock, used-data-element=LogDataEvnt3_SucAuthAndEnhanceRights}
          service-needs:
            nv block needs NvM_SecLog_LogDataEvnt3_SucAuthAndEnhanceRights: ram-block-status-control=API, restore-at-start=true, store-at-shutdown=true
        NvM_SecLog_LogDataEvnt4_AuthBySecAccess: assigned-datas=role-based-data-assignment={role=ramBlock, used-data-element=LogDataEvnt4_AuthBySecAccess}
          service-needs:
            nv block needs NvM_SecLog_LogDataEvnt4_AuthBySecAccess: ram-block-status-control=API, restore-at-start=true, store-at-shutdown=true
        NvM_SecLog_LogDataEvnt5_SucDiagServiceExec: assigned-datas=role-based-data-assignment={role=ramBlock, used-data-element=LogDataEvnt5_SucDiagServiceExec}
          service-needs:
            nv block needs NvM_SecLog_LogDataEvnt5_SucDiagServiceExec: ram-block-status-control=API, restore-at-start=true, store-at-shutdown=true
        NvM_SecLog_LogDataEvnt6_RightsMgmt: assigned-datas=role-based-data-assignment={role=ramBlock, used-data-element=LogDataEvnt6_RightsMgmt}
          service-needs:
            nv block needs NvM_SecLog_LogDataEvnt6_RightsMgmt: ram-block-status-control=API, restore-at-start=true, store-at-shutdown=true
        NvM_SecLog_LogDataEvnt7_SigVerif: assigned-datas=role-based-data-assignment={role=ramBlock, used-data-element=LogDataEvnt7_SigVerif}
          service-needs:
            nv block needs NvM_SecLog_LogDataEvnt7_SigVerif: ram-block-status-control=API, restore-at-start=true, store-at-shutdown=true
        NvM_SecLog_LogDataEvnt8_TickCountDateAndTime: assigned-datas=role-based-data-assignment={role=ramBlock, used-data-element=LogDataEvnt8_TickCountDateAndTime}
          service-needs:
            nv block needs NvM_SecLog_LogDataEvnt8_TickCountDateAndTime: ram-block-status-control=API, restore-at-start=true, store-at-shutdown=true
        NvM_SecLog_LogDataEvnt9_SecOcMisconfig: assigned-datas=role-based-data-assignment={role=ramBlock, used-data-element=LogDataEvnt9_SecOcMisconfig}
          service-needs:
            nv block needs NvM_SecLog_LogDataEvnt9_SecOcMisconfig: ram-block-status-control=API, restore-at-start=true, store-at-shutdown=true
        NvM_SecLog_LogDataEvnt10_FailedPduMacVerif: assigned-datas=role-based-data-assignment={role=ramBlock, used-data-element=LogDataEvnt10_FailedPduMacVerif}
          service-needs:
            nv block needs NvM_SecLog_LogDataEvnt10_FailedPduMacVerif: ram-block-status-control=API, restore-at-start=true, store-at-shutdown=true
        NvM_SecLog_LogDataEvnt11_SecOrAuthBoot: assigned-datas=role-based-data-assignment={role=ramBlock, used-data-element=LogDataEvnt11_SecOrAuthBoot}
          service-needs:
            nv block needs NvM_SecLog_LogDataEvnt11_SecOrAuthBoot: ram-block-status-control=API, restore-at-start=true, store-at-shutdown=true
        NvM_SecLog_LogDataEvnt12_ChangeOfVin: assigned-datas=role-based-data-assignment={role=ramBlock, used-data-element=LogDataEvnt12_ChangeOfVin}
          service-needs:
            nv block needs NvM_SecLog_LogDataEvnt12_ChangeOfVin: ram-block-status-control=API, restore-at-start=true, store-at-shutdown=true
        NvM_SecLog_LogDataEvnt13_AclReplacement: assigned-datas=role-based-data-assignment={role=ramBlock, used-data-element=LogDataEvnt13_AclReplacement}
          service-needs:
            nv block needs NvM_SecLog_LogDataEvnt13_AclReplacement: ram-block-status-control=API, restore-at-start=true, store-at-shutdown=true
        NvM_SecLog_LogFailedMacVerifCount_ExceededTh1: assigned-datas=role-based-data-assignment={role=ramBlock, used-data-element=LogFailedMacVerifCount_ExceededTh1}
          service-needs:
            nv block needs NvM_SecLog_LogFailedMacVerifCount_ExceededTh1: ram-block-status-control=API, restore-at-start=true, store-at-shutdown=true
        NvM_SecLog_LogFailedMacVerifCount_ExceededTh2: assigned-datas=role-based-data-assignment={role=ramBlock, used-data-element=LogFailedMacVerifCount_ExceededTh2}
          service-needs:
            nv block needs NvM_SecLog_LogFailedMacVerifCount_ExceededTh2: ram-block-status-control=API, restore-at-start=true, store-at-shutdown=true
        NvM_SecLog_LogFailedMacVerifCount_ExceededTh3: assigned-datas=role-based-data-assignment={role=ramBlock, used-data-element=LogFailedMacVerifCount_ExceededTh3}
          service-needs:
            nv block needs NvM_SecLog_LogFailedMacVerifCount_ExceededTh3: ram-block-status-control=API, restore-at-start=true, store-at-shutdown=true
      shared-parameters:
        parameter data prototype NvM_SecLog_CtrlData_DefaultValue: type=SecLog_CtrlDataType, init-value=13 x fields=[ElementConstant:0, ElementConstant_1:0, ElementConstant_2:0]
  swc implementation Ssa_SecLog_Implementation: behavior=Ssa_SecLog_InternalBehavior
    code-descriptors:
      code Default: artifact-descriptors=autosar-engineering-object=category=SWSRC
